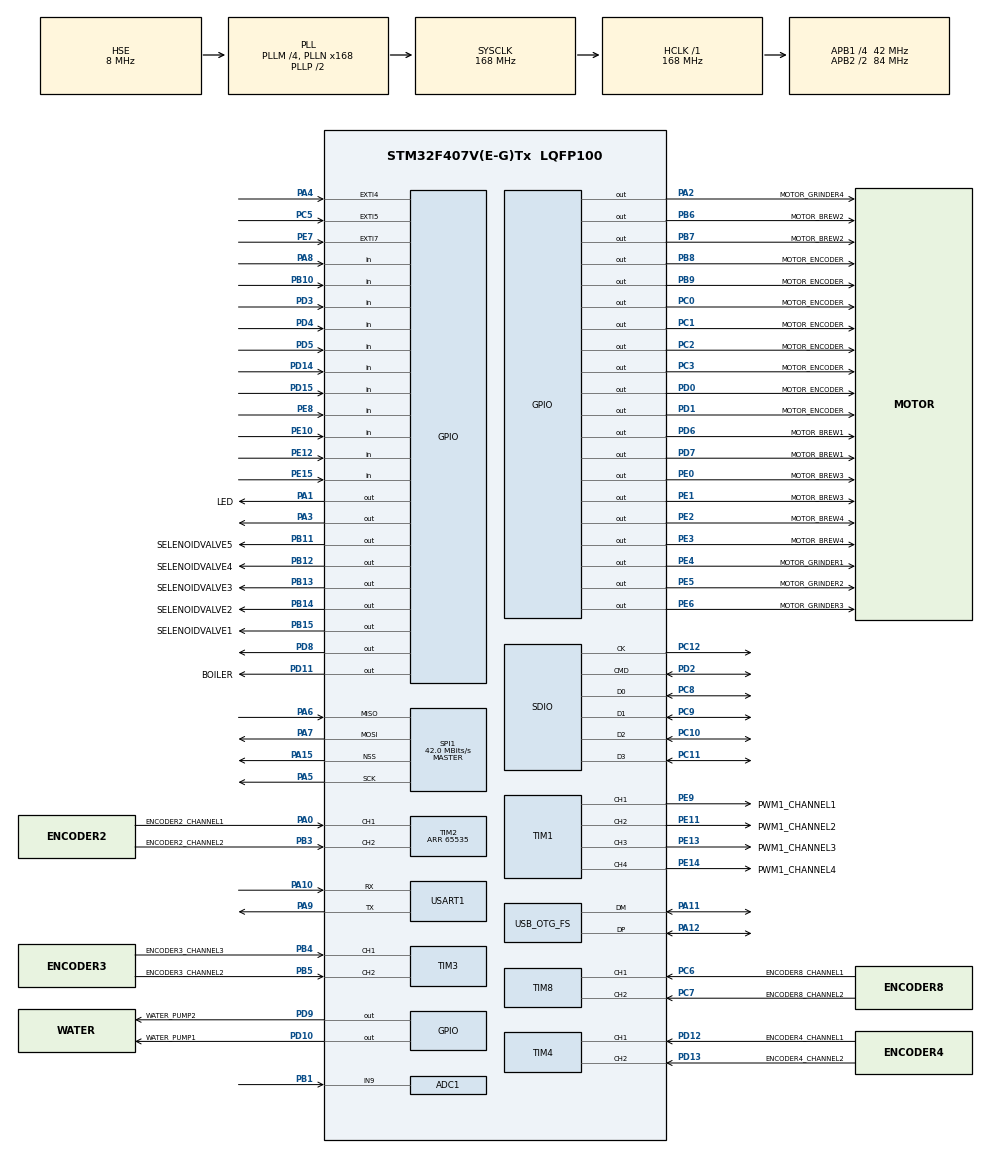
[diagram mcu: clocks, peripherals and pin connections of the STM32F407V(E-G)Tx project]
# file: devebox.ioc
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ADC1.Channel-0\#ChannelRegularConversion=ADC_CHANNEL_9
ADC1.ContinuousConvMode=ENABLE
ADC1.NbrOfConversionFlag=1
ADC1.Rank-0\#ChannelRegularConversion=1
ADC1.SamplingTime-0\#ChannelRegularConversion=ADC_SAMPLETIME_3CYCLES
ADC1.ScanConvMode=ENABLE
ADC1.master=1
Dma.ADC1.1.Direction=DMA_PERIPH_TO_MEMORY
Dma.ADC1.1.FIFOMode=DMA_FIFOMODE_DISABLE
Dma.ADC1.1.Instance=DMA2_Stream0
Dma.ADC1.1.MemDataAlignment=DMA_MDATAALIGN_WORD
Dma.ADC1.1.MemInc=DMA_MINC_ENABLE
Dma.ADC1.1.Mode=DMA_NORMAL
Dma.ADC1.1.PeriphDataAlignment=DMA_PDATAALIGN_WORD
Dma.ADC1.1.PeriphInc=DMA_PINC_DISABLE
Dma.ADC1.1.Priority=DMA_PRIORITY_LOW
Dma.Request0=USART1_RX
Dma.Request1=ADC1
Dma.USART1_RX.0.Direction=DMA_PERIPH_TO_MEMORY
Dma.USART1_RX.0.FIFOMode=DMA_FIFOMODE_DISABLE
Dma.USART1_RX.0.Instance=DMA2_Stream2
Dma.USART1_RX.0.MemDataAlignment=DMA_MDATAALIGN_BYTE
Dma.USART1_RX.0.MemInc=DMA_MINC_ENABLE
Dma.USART1_RX.0.Mode=DMA_NORMAL
Dma.USART1_RX.0.PeriphDataAlignment=DMA_PDATAALIGN_BYTE
Dma.USART1_RX.0.PeriphInc=DMA_PINC_DISABLE
Dma.USART1_RX.0.Priority=DMA_PRIORITY_LOW
FATFS.BSP.number=1
FATFS0.BSP.STBoard=false
FATFS0.BSP.api=Unknown
FATFS0.BSP.instance=PA8
FATFS0.BSP.ip=GPIO
FATFS0.BSP.mode=Input
FATFS0.BSP.name=Detect_SDIO
FATFS0.BSP.solution=PA8
FREERTOS.Tasks01=defaultTask,24,128,StartDefaultTask,Default,NULL,Static,defaultTaskBuffer,defaultTaskControlBlock
FREERTOS.configCHECK_FOR_STACK_OVERFLOW=1
FREERTOS.configUSE_DAEMON_TASK_STARTUP_HOOK=1
FREERTOS.configUSE_IDLE_HOOK=1
FREERTOS.configUSE_MALLOC_FAILED_HOOK=1
FREERTOS.configUSE_NEWLIB_REENTRANT=1
FREERTOS.configUSE_TICK_HOOK=1
IWDG.Reload=4000
Mcu.Family=STM32F4
Mcu.Name=STM32F407V(E-G)Tx
Mcu.Package=LQFP100
NVIC.DMA2_Stream0_IRQn=true\:5\:0\:false\:false\:true\:true\:false\:true\:true
NVIC.DMA2_Stream2_IRQn=true\:5\:0\:false\:false\:true\:true\:false\:true\:true
NVIC.EXTI4_IRQn=true\:5\:0\:false\:false\:true\:true\:true\:true\:true
NVIC.EXTI9_5_IRQn=true\:5\:0\:false\:false\:true\:true\:true\:true\:true
NVIC.OTG_FS_IRQn=true\:5\:0\:false\:false\:true\:true\:false\:true\:true
NVIC.PriorityGroup=NVIC_PRIORITYGROUP_4
NVIC.TIM2_IRQn=true\:5\:0\:false\:false\:true\:true\:true\:true\:true
NVIC.TIM4_IRQn=true\:5\:0\:false\:false\:true\:true\:true\:true\:true
NVIC.TIM8_TRG_COM_TIM14_IRQn=true\:15\:0\:false\:false\:true\:false\:false\:true\:true
NVIC.TimeBase=TIM8_TRG_COM_TIM14_IRQn
NVIC.TimeBaseIP=TIM14
NVIC.USART1_IRQn=true\:5\:0\:true\:false\:true\:true\:true\:true\:true
PA0-WKUP.GPIO_Label=ENCODER2_CHANNEL1
PA0-WKUP.Signal=S_TIM2_CH1_ETR
PA1.GPIO_Label=LED
PA1.Signal=GPIO_Output
PA10.Mode=Asynchronous
PA10.Signal=USART1_RX
PA11.Mode=Device_Only
PA11.Signal=USB_OTG_FS_DM
PA12.Mode=Device_Only
PA12.Signal=USB_OTG_FS_DP
PA13.Mode=Serial_Wire
PA13.Signal=SYS_JTMS-SWDIO
PA14.Mode=Serial_Wire
PA14.Signal=SYS_JTCK-SWCLK
PA15.Mode=NSS_Signal_Hard_Output
PA15.Signal=SPI1_NSS
PA2.GPIO_Label=MOTOR_GRINDER4
PA2.Signal=GPIO_Output
PA3.Signal=GPIO_Output
PA4.Signal=GPXTI4
PA5.Mode=Full_Duplex_Master
PA5.Signal=SPI1_SCK
PA6.Mode=Full_Duplex_Master
PA6.Signal=SPI1_MISO
PA7.Mode=Full_Duplex_Master
PA7.Signal=SPI1_MOSI
PA8.GPIO_PuPd=GPIO_PULLUP
PA8.Signal=GPIO_Input
PA9.Mode=Asynchronous
PA9.Signal=USART1_TX
PB1.Signal=ADCx_IN9
PB10.GPIO_PuPd=GPIO_PULLUP
PB10.Signal=GPIO_Input
PB11.GPIO_Label=SELENOIDVALVE5
PB11.Signal=GPIO_Output
PB12.GPIO_Label=SELENOIDVALVE4
PB12.Signal=GPIO_Output
PB13.GPIO_Label=SELENOIDVALVE3
PB13.Signal=GPIO_Output
PB14.GPIO_Label=SELENOIDVALVE2
PB14.Signal=GPIO_Output
PB15.GPIO_Label=SELENOIDVALVE1
PB15.Signal=GPIO_Output
PB3.GPIO_Label=ENCODER2_CHANNEL2
PB3.Signal=S_TIM2_CH2
PB4.GPIO_Label=ENCODER3_CHANNEL3
PB4.Signal=S_TIM3_CH1
PB5.GPIO_Label=ENCODER3_CHANNEL2
PB5.Signal=S_TIM3_CH2
PB6.GPIO_Label=MOTOR_BREW2
PB6.Signal=GPIO_Output
PB7.GPIO_Label=MOTOR_BREW2
PB7.Signal=GPIO_Output
PB8.GPIO_Label=MOTOR_ENCODER
PB8.Signal=GPIO_Output
PB9.GPIO_Label=MOTOR_ENCODER
PB9.Signal=GPIO_Output
PC0.GPIO_Label=MOTOR_ENCODER
PC0.Signal=GPIO_Output
PC1.GPIO_Label=MOTOR_ENCODER
PC1.Signal=GPIO_Output
PC10.Mode=SD_4_bits_Wide_bus
PC10.Signal=SDIO_D2
PC11.Mode=SD_4_bits_Wide_bus
PC11.Signal=SDIO_D3
PC12.Mode=SD_4_bits_Wide_bus
PC12.Signal=SDIO_CK
PC14-OSC32_IN.Mode=LSE-External-Oscillator
PC14-OSC32_IN.Signal=RCC_OSC32_IN
PC15-OSC32_OUT.Mode=LSE-External-Oscillator
PC15-OSC32_OUT.Signal=RCC_OSC32_OUT
PC2.GPIO_Label=MOTOR_ENCODER
PC2.Signal=GPIO_Output
PC3.GPIO_Label=MOTOR_ENCODER
PC3.Signal=GPIO_Output
PC5.Signal=GPXTI5
PC6.GPIO_Label=ENCODER8_CHANNEL1
PC6.Signal=S_TIM8_CH1
PC7.GPIO_Label=ENCODER8_CHANNEL2
PC7.Signal=S_TIM8_CH2
PC8.Mode=SD_4_bits_Wide_bus
PC8.Signal=SDIO_D0
PC9.Mode=SD_4_bits_Wide_bus
PC9.Signal=SDIO_D1
PD0.GPIO_Label=MOTOR_ENCODER
PD0.Signal=GPIO_Output
PD1.GPIO_Label=MOTOR_ENCODER
PD1.Signal=GPIO_Output
PD10.GPIO_Label=WATER_PUMP1
PD10.Signal=GPIO_Output
PD11.GPIO_Label=BOILER
PD11.Signal=GPIO_Output
PD12.GPIO_Label=ENCODER4_CHANNEL1
PD12.Signal=S_TIM4_CH1
PD13.GPIO_Label=ENCODER4_CHANNEL2
PD13.Signal=S_TIM4_CH2
PD14.GPIO_PuPd=GPIO_PULLUP
PD14.Signal=GPIO_Input
PD15.GPIO_PuPd=GPIO_PULLUP
PD15.Signal=GPIO_Input
PD2.Mode=SD_4_bits_Wide_bus
PD2.Signal=SDIO_CMD
PD3.GPIO_PuPd=GPIO_PULLUP
PD3.Signal=GPIO_Input
PD4.GPIO_PuPd=GPIO_PULLUP
PD4.Signal=GPIO_Input
PD5.GPIO_PuPd=GPIO_PULLUP
PD5.Signal=GPIO_Input
PD6.GPIO_Label=MOTOR_BREW1
PD6.Signal=GPIO_Output
PD7.GPIO_Label=MOTOR_BREW1
PD7.Signal=GPIO_Output
PD8.Signal=GPIO_Output
PD9.GPIO_Label=WATER_PUMP2
PD9.Signal=GPIO_Output
PE0.GPIO_Label=MOTOR_BREW3
PE0.Signal=GPIO_Output
PE1.GPIO_Label=MOTOR_BREW3
PE1.Signal=GPIO_Output
PE10.GPIO_PuPd=GPIO_PULLUP
PE10.Signal=GPIO_Input
PE11.GPIO_Label=PWM1_CHANNEL2
PE11.Signal=S_TIM1_CH2
PE12.GPIO_PuPd=GPIO_PULLUP
PE12.Signal=GPIO_Input
PE13.GPIO_Label=PWM1_CHANNEL3
PE13.Signal=S_TIM1_CH3
PE14.GPIO_Label=PWM1_CHANNEL4
PE14.Signal=S_TIM1_CH4
PE15.GPIO_PuPd=GPIO_PULLUP
PE15.Signal=GPIO_Input
PE2.GPIO_Label=MOTOR_BREW4
PE2.Signal=GPIO_Output
PE3.GPIO_Label=MOTOR_BREW4
PE3.Signal=GPIO_Output
PE4.GPIO_Label=MOTOR_GRINDER1
PE4.Signal=GPIO_Output
PE5.GPIO_Label=MOTOR_GRINDER2
PE5.Signal=GPIO_Output
PE6.GPIO_Label=MOTOR_GRINDER3
PE6.Signal=GPIO_Output
PE7.Signal=GPXTI7
PE8.Signal=GPIO_Input
PE9.GPIO_Label=PWM1_CHANNEL1
PE9.Signal=S_TIM1_CH1
PH0-OSC_IN.Mode=HSE-External-Oscillator
PH0-OSC_IN.Signal=RCC_OSC_IN
PH1-OSC_OUT.Mode=HSE-External-Oscillator
PH1-OSC_OUT.Signal=RCC_OSC_OUT
ProjectManager.HeapSize=0x200
ProjectManager.StackSize=0x400
ProjectManager.TargetToolchain=STM32CubeIDE
RCC.48MHZClocksFreq_Value=48000000
RCC.AHBFreq_Value=168000000
RCC.APB1CLKDivider=RCC_HCLK_DIV4
RCC.APB1Freq_Value=42000000
RCC.APB1TimFreq_Value=84000000
RCC.APB2CLKDivider=RCC_HCLK_DIV2
RCC.APB2Freq_Value=84000000
RCC.APB2TimFreq_Value=168000000
RCC.CortexFreq_Value=168000000
RCC.HCLKFreq_Value=168000000
RCC.HSE_VALUE=8000000
RCC.HSI_VALUE=16000000
RCC.PLLM=4
RCC.PLLN=168
RCC.PLLQ=7
RCC.SYSCLKFreq_VALUE=168000000
RCC.SYSCLKSource=RCC_SYSCLKSOURCE_PLLCLK
RCC.VCOOutputFreq_Value=336000000
SH.ADCx_IN9.0=ADC1_IN9,IN9
SH.S_TIM1_CH1.0=TIM1_CH1,PWM Generation1 CH1
SH.S_TIM1_CH2.0=TIM1_CH2,PWM Generation2 CH2
SH.S_TIM1_CH3.0=TIM1_CH3,PWM Generation3 CH3
SH.S_TIM1_CH4.0=TIM1_CH4,PWM Generation4 CH4
SH.S_TIM2_CH1_ETR.0=TIM2_CH1,Encoder_Interface
SH.S_TIM2_CH2.0=TIM2_CH2,Encoder_Interface
SH.S_TIM3_CH1.0=TIM3_CH1,Encoder_Interface
SH.S_TIM3_CH2.0=TIM3_CH2,Encoder_Interface
SH.S_TIM4_CH1.0=TIM4_CH1,Encoder_Interface
SH.S_TIM4_CH2.0=TIM4_CH2,Encoder_Interface
SH.S_TIM8_CH1.0=TIM8_CH1,Encoder_Interface
SH.S_TIM8_CH2.0=TIM8_CH2,Encoder_Interface
SPI1.CalculateBaudRate=42.0 MBits/s
SPI1.Direction=SPI_DIRECTION_2LINES
SPI1.Mode=SPI_MODE_MASTER
SPI1.VirtualNSS=VM_NSSHARD
SPI1.VirtualType=VM_MASTER
TIM1.Channel-PWM\ Generation1\ CH1=TIM_CHANNEL_1
TIM1.Channel-PWM\ Generation2\ CH2=TIM_CHANNEL_2
TIM1.Channel-PWM\ Generation3\ CH3=TIM_CHANNEL_3
TIM1.Channel-PWM\ Generation4\ CH4=TIM_CHANNEL_4
TIM2.EncoderMode=TIM_ENCODERMODE_TI12
TIM2.Period=65535
TIM4.EncoderMode=TIM_ENCODERMODE_TI12
TIM8.EncoderMode=TIM_ENCODERMODE_TI12
USART1.VirtualMode=VM_ASYNC
USB_DEVICE.CLASS_NAME_FS=CDC
USB_DEVICE.VirtualMode-CDC_FS=Cdc
USB_DEVICE.VirtualModeFS=Cdc_FS
USB_OTG_FS.VirtualMode=Device_Only
VP_FATFS_VS_SDIO.Mode=SDIO
VP_FREERTOS_VS_CMSIS_V2.Mode=CMSIS_V2
VP_IWDG_VS_IWDG.Mode=IWDG_Activate
VP_SYS_VS_tim14.Mode=TIM14
VP_USB_DEVICE_VS_USB_DEVICE_CDC_FS.Mode=CDC_FS
board=custom

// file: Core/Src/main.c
/* USER CODE BEGIN Header */
/**
  ******************************************************************************
  * @file           : main.c
  * @brief          : Main program body
  ******************************************************************************
  * @attention
  *
  * Copyright (c) 2024 STMicroelectronics.
  * All rights reserved.
  *
  * This software is licensed under terms that can be found in the LICENSE file
  * in the root directory of this software component.
  * If no LICENSE file comes with this software, it is provided AS-IS.
  *
  ******************************************************************************
  */
/* USER CODE END Header */
#include "main.h"
#include "cmsis_os.h"
#include "adc.h"
#include "dma.h"
#include "fatfs.h"
#include "iwdg.h"
#include "sdio.h"
#include "spi.h"
#include "tim.h"
#include "usart.h"
#include "usb_device.h"
#include "gpio.h"

/* USER CODE BEGIN Includes */
#include <stdarg.h>
/* USER CODE END Includes */

void SystemClock_Config(void);
void MX_FREERTOS_Init(void);
/* USER CODE BEGIN PFP */
__weak void project_init(void) {}
__weak void panic(const char* msg) { UNUSED(msg); }

#ifndef FORMAT_BUFFER_SIZE
#define FORMAT_BUFFER_SIZE 128
#endif

char* f(const char* fmt, ...) {
  static char str[FORMAT_BUFFER_SIZE];
  va_list vl;
  va_start(vl, fmt);
  vsnprintf(str, sizeof(str), fmt, vl);
  va_end(vl);
  return str;
}
/* USER CODE END PFP */

int main(void)
{

  /* MCU Configuration--------------------------------------------------------*/

  /* Reset of all peripherals, Initializes the Flash interface and the Systick. */
  HAL_Init();

  /* Configure the system clock */
  SystemClock_Config();

  /* Initialize all configured peripherals */
  MX_GPIO_Init();
  MX_DMA_Init();
  MX_ADC1_Init();
  MX_IWDG_Init();
  MX_SDIO_SD_Init();
  MX_SPI1_Init();
  MX_TIM1_Init();
  MX_TIM2_Init();
  MX_TIM3_Init();
  MX_TIM4_Init();
  MX_TIM8_Init();
  MX_USART1_UART_Init();
  MX_FATFS_Init();
  /* USER CODE BEGIN 2 */
  project_init();
  /* USER CODE END 2 */

  /* Init scheduler */
  osKernelInitialize();

  /* Call init function for freertos objects (in cmsis_os2.c) */
  MX_FREERTOS_Init();

  /* Start scheduler */
  osKernelStart();

  /* We should never get here as control is now taken by the scheduler */

  /* Infinite loop */
  while (1)
  {

  }
}

void SystemClock_Config(void)
{
  RCC_OscInitTypeDef RCC_OscInitStruct = {0};
  RCC_ClkInitTypeDef RCC_ClkInitStruct = {0};

  /** Configure the main internal regulator output voltage
  */
  __HAL_RCC_PWR_CLK_ENABLE();
  __HAL_PWR_VOLTAGESCALING_CONFIG(PWR_REGULATOR_VOLTAGE_SCALE1);

  /** Initializes the RCC Oscillators according to the specified parameters
  * in the RCC_OscInitTypeDef structure.
  */
  RCC_OscInitStruct.OscillatorType = RCC_OSCILLATORTYPE_LSI|RCC_OSCILLATORTYPE_HSE;
  RCC_OscInitStruct.HSEState = RCC_HSE_ON;
  RCC_OscInitStruct.LSIState = RCC_LSI_ON;
  RCC_OscInitStruct.PLL.PLLState = RCC_PLL_ON;
  RCC_OscInitStruct.PLL.PLLSource = RCC_PLLSOURCE_HSE;
  RCC_OscInitStruct.PLL.PLLM = 4;
  RCC_OscInitStruct.PLL.PLLN = 168;
  RCC_OscInitStruct.PLL.PLLP = RCC_PLLP_DIV2;
  RCC_OscInitStruct.PLL.PLLQ = 7;
  if (HAL_RCC_OscConfig(&RCC_OscInitStruct) != HAL_OK)
  {
    Error_Handler();
  }

  /** Initializes the CPU, AHB and APB buses clocks
  */
  RCC_ClkInitStruct.ClockType = RCC_CLOCKTYPE_HCLK|RCC_CLOCKTYPE_SYSCLK
                              |RCC_CLOCKTYPE_PCLK1|RCC_CLOCKTYPE_PCLK2;
  RCC_ClkInitStruct.SYSCLKSource = RCC_SYSCLKSOURCE_PLLCLK;
  RCC_ClkInitStruct.AHBCLKDivider = RCC_SYSCLK_DIV1;
  RCC_ClkInitStruct.APB1CLKDivider = RCC_HCLK_DIV4;
  RCC_ClkInitStruct.APB2CLKDivider = RCC_HCLK_DIV2;

  if (HAL_RCC_ClockConfig(&RCC_ClkInitStruct, FLASH_LATENCY_5) != HAL_OK)
  {
    Error_Handler();
  }
}

void HAL_TIM_PeriodElapsedCallback(TIM_HandleTypeDef *htim)
{
  if (htim->Instance == TIM14) {
    HAL_IncTick();
  }
}

void Error_Handler(void)
{
  __disable_irq();
  while (1)
  {
  }
}

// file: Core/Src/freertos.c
/* USER CODE BEGIN Header */
/**
  ******************************************************************************
  * File Name          : freertos.c
  * Description        : Code for freertos applications
  ******************************************************************************
  * @attention
  *
  * Copyright (c) 2024 STMicroelectronics.
  * All rights reserved.
  *
  * This software is licensed under terms that can be found in the LICENSE file
  * in the root directory of this software component.
  * If no LICENSE file comes with this software, it is provided AS-IS.
  *
  ******************************************************************************
  */
/* USER CODE END Header */

#include "FreeRTOS.h"
#include "task.h"
#include "main.h"
#include "cmsis_os.h"

/* USER CODE BEGIN Includes */
#include "iwdg.h"
/* USER CODE END Includes */

typedef StaticTask_t osStaticThreadDef_t;

/* USER CODE BEGIN Variables */
char blinkSymbols[16] = "1010";
int blinky_is_running = 1;
uint32_t blinky_delay = 150;
/* USER CODE END Variables */
/* Definitions for defaultTask */
osThreadId_t defaultTaskHandle;
uint32_t defaultTaskBuffer[ 128 ];
osStaticThreadDef_t defaultTaskControlBlock;
const osThreadAttr_t defaultTask_attributes = {
  .name = "defaultTask",
  .cb_mem = &defaultTaskControlBlock,
  .cb_size = sizeof(defaultTaskControlBlock),
  .stack_mem = &defaultTaskBuffer[0],
  .stack_size = sizeof(defaultTaskBuffer),
  .priority = (osPriority_t) osPriorityNormal,
};

/* USER CODE BEGIN FunctionPrototypes */
void panic(const char* msg);
char* f(const char* fmt, ...);
/* USER CODE END FunctionPrototypes */

void StartDefaultTask(void *argument);

extern void MX_USB_DEVICE_Init(void);
void MX_FREERTOS_Init(void); /* (MISRA C 2004 rule 8.1) */

/* Hook prototypes */
void vApplicationIdleHook(void);
void vApplicationTickHook(void);
void vApplicationStackOverflowHook(xTaskHandle xTask, signed char *pcTaskName);
void vApplicationMallocFailedHook(void);
void vApplicationDaemonTaskStartupHook(void);

/* USER CODE BEGIN 2 */
void vApplicationIdleHook( void )
{
   /* vApplicationIdleHook() will only be called if configUSE_IDLE_HOOK is set
   to 1 in FreeRTOSConfig.h. It will be called on each iteration of the idle
   task. It is essential that code added to this hook function never attempts
   to block in any way (for example, call xQueueReceive() with a block time
   specified, or call vTaskDelay()). If the application makes use of the
   vTaskDelete() API function (as this demo application does) then it is also
   important that vApplicationIdleHook() is permitted to return to its calling
   function, because it is the responsibility of the idle task to clean up
   memory allocated by the kernel to any task that has since been deleted. */
  HAL_IWDG_Refresh(&hiwdg);
}
/* USER CODE END 2 */

/* USER CODE BEGIN 3 */
void vApplicationTickHook( void )
{
   /* This function will be called by each tick interrupt if
   configUSE_TICK_HOOK is set to 1 in FreeRTOSConfig.h. User code can be
   added here, but the tick hook is called from an interrupt context, so
   code must not attempt to block, and only the interrupt safe FreeRTOS API
   functions can be used (those that end in FromISR()). */
}
/* USER CODE END 3 */

/* USER CODE BEGIN 4 */
void vApplicationStackOverflowHook(xTaskHandle xTask, signed char *pcTaskName)
{
   /* Run time stack overflow checking is performed if
   configCHECK_FOR_STACK_OVERFLOW is defined to 1 or 2. This hook function is
   called if a stack overflow is detected. */
  if (pcTaskName) {
    panic(f("Stack overflow on thread %s", pcTaskName));
  } else {
    panic(f("Stack overflow on thread %u", (size_t)xTask));
  }
}
/* USER CODE END 4 */

/* USER CODE BEGIN 5 */
void vApplicationMallocFailedHook(void)
{
   /* vApplicationMallocFailedHook() will only be called if
   configUSE_MALLOC_FAILED_HOOK is set to 1 in FreeRTOSConfig.h. It is a hook
   function that will get called if a call to pvPortMalloc() fails.
   pvPortMalloc() is called internally by the kernel whenever a task, queue,
   timer or semaphore is created. It is also called by various parts of the
   demo application. If heap_1.c or heap_2.c are used, then the size of the
   heap available to pvPortMalloc() is defined by configTOTAL_HEAP_SIZE in
   FreeRTOSConfig.h, and the xPortGetFreeHeapSize() API function can be used
   to query the size of free heap space that remains (although it does not
   provide information on how the remaining heap might be fragmented). */
  panic("Fail to allocate dynamic memory");
}
/* USER CODE END 5 */

/* USER CODE BEGIN DAEMON_TASK_STARTUP_HOOK */
void vApplicationDaemonTaskStartupHook(void)
{
}
/* USER CODE END DAEMON_TASK_STARTUP_HOOK */

void MX_FREERTOS_Init(void) {

  /* Create the thread(s) */
  /* creation of defaultTask */
  defaultTaskHandle = osThreadNew(StartDefaultTask, NULL, &defaultTask_attributes);

}

void StartDefaultTask(void *argument)
{
  /* init code for USB_DEVICE */
  MX_USB_DEVICE_Init();
  /* USER CODE BEGIN StartDefaultTask */
  HAL_GPIO_WritePin(LED_GPIO_Port, LED_Pin, GPIO_PIN_SET);
  /* Infinite loop */
  while (blinky_is_running)
  {
    for (size_t i = 0; i < sizeof(blinkSymbols); i++) {
      if (blinkSymbols[i] == '\0') break;
      switch (blinkSymbols[i]) {
        case '1': HAL_GPIO_WritePin(LED_GPIO_Port, LED_Pin, GPIO_PIN_RESET); osDelay(blinky_delay); break;
        case '0': HAL_GPIO_WritePin(LED_GPIO_Port, LED_Pin, GPIO_PIN_SET); osDelay(blinky_delay); break;
        default: break;
      }
    }
    osDelay(500);
  }
  osThreadExit();
  /* USER CODE END StartDefaultTask */
}
